# STM32WB09 register map
File version: 1.0
CPU: CM0+ r0p0, little endian, MPU, no FPU, 2 interrupt priority bits
Registers are 32-bit, read-write, reset 0x0 unless marked. A register's access mark holds for its fields unless they carry their own. Offsets are from the block's base; [hi:lo] are bit positions.

## IWDG
Base 0x40003000
0x00 KR 16-bit — IWDG_KR register
  [15:0] KEY wo — Key value. Software can only write these bits. Reading returns the reset value. These bits must be written by software at regular intervals with the key value 0xAAAA, otherwise the watchdog generates a reset when the counter reaches 0. Writing the key value 0x5555 to enables access to the IWDG_PR, IWDG_RLR and IWDG_WINR registers. Writing the key value CCCCh starts the watchdog
    0x5555=Unlock (Enable access to PR, RLR and WINR registers); 0xAAAA=Feed watchdog with RLR register value; 0xCCCC=Start the watchdog
0x04 PR 16-bit — IWDG_PR register
  [2:0] PR — Prescaler divider. Set and reset by software. These bits are write access protected. They are written by software to select the prescaler divider feeding the counter clock. PVU bit of IWDG_SR must be reset in order to be able to change the prescaler divider. 000: divider/4 001: divider/8 010: divider/16 011: divider/32 100: divider/64 101: divider/128 110: divider/256 111: divider/256
    0=DivideBy4 (Divider /4); 1=DivideBy8 (Divider /8); 2=DivideBy16 (Divider /16); 3=DivideBy32 (Divider /32); 4=DivideBy64 (Divider /64); 5=DivideBy128 (Divider /128); other=DivideBy256 (Divider /256)
0x08 RLR 16-bit reset 0xFFF — IWDG_RLR register
  [11:0] RL — Watchdog counter reload value. Set and reset by software. These bits are write access protected. They are written by software to define the value to be loaded in the watchdog counter each time the value 0xAAAA is written in the IWDG_KR register. The watchdog counter counts down from this value. The timeout period is a function of this value and the clock prescaler. The RVU bit in the IWDG_SR register must be reset in order to be able to change the reload value.
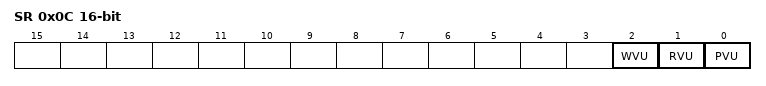
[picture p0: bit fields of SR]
0x0C SR 16-bit ro — IWDG_SR register
  [2] WVU — Watchdog counter window value update. Read only bit. This bit is set by hardware to indicate that an update of the window value is ongoing. It is reset by hardware when the reload value update operation is completed in the VDD voltage domain (takes up to 5 RC 40 kHz cycles). Window value can be updated only when WVU bit is reset. This bit is generated only if generic 'window' = 1
  [1] RVU — Watchdog counter reload value update. Read only bit. This bit is set by hardware to indicate that an update of the reload value is ongoing. It is reset by hardware when the reload value update operation is completed in the VDD voltage domain (takes up to 5 RC 40 kHz cycles). Reload value can be updated only when RVU bit is reset
  [0] PVU — Watchdog prescaler value update. Read only bit. This bit is set by hardware to indicate that an update of the prescaler value is ongoing. It is reset by hardware when the prescaler update operation is completed in the VDD voltage domain (takes up to 5 RC 40 kHz cycles). Prescaler value can be updated only when PVU bit is reset
0x10 WINR 16-bit reset 0xFFF — IWDG_WINR register
  [11:0] WIN — Watchdog counter window value. Set and reset by software. These bits are write access protected. These bits contain the high limit of the window value to be compared to the downcounter. To prevent a reset, the downcounter must be reloaded when its value is lower than the window register value and greater than 0x0 The WVU bit in the IWDG_SR register must be reset in order to be able to change the reload value.

## PKA
Base 0x48300000
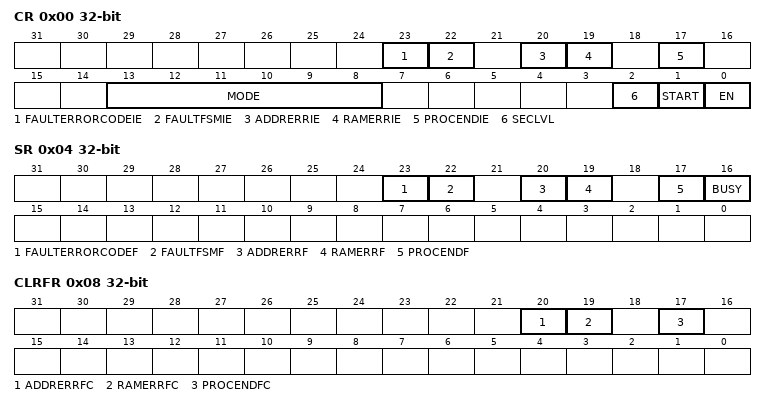
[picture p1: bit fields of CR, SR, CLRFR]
0x00 CR — PKA_CR register
  [23] FAULTERRORCODEIE — Fault error code interrupt enable 0: Interrupt is disabled. 1: An interrupt is generated when FAULTERRORCODEF (PKA_SR[23]) is set.
  [22] FAULTFSMIE — Fault FSM interrupt enable 0: Interrupt is disabled. 1: An interrupt is generated when FAULTFSMF (PKA_SR[22]) is set.
  [20] ADDRERRIE — Address error interrupt enable 0: Interrupt is disabled. 1: An interrupt is generated when ADDRERRF (PKA_SR[20]) is set.
  [19] RAMERRIE — RAM error interrupt enable 0: Interrupt is disabled. 1: An interrupt is generated when RAMERRF (PKA_SR[19]) is set.
  [17] PROCENDIE — End of operation interrupt enable 0: Interrupt is disabled. 1: An interrupt is generated when PROCENDF (PKA_SR[17]) is set.
  [13:8] MODE — PKA operation code 000000 : Compute Montgomery parameter and modular exponentiation 000001 : Compute Montgomery parameter 000010 : Compute modular exponentiation only (Montgomery parameter should be loaded) 100000 : Compute Montgomery parameter and compute ECC kP operation 100010 : Compute the ECC kP primitive only (Montgomery parameter should be loaded) 100100 : ECDSA sign 100110 : ECDSA Verification 101000 : Point Check 000111 : RSA CRT exponentiation 001000 : Modular inversion 001001 : Arithmetic addition 001010 : Arithmetic Subtraction 001011 : Arithmetic multiplication 001100 : Comparison 001101 : Modular Reduction 001110 : Modular Addition 001111 : Modular Subtraction 010000 : Montgomery Multiplication
  [2] SECLVL — Security enable. 0: No side channel countermeasure 1: Square and Multiply always / Double and Add always
  [1] START — Start the operation 0: No operation 1: Writing '1' to this bit starts the operation which is selected by MODE[5:0], using the operands and data already written to the PKA RAM. This bit is always read as '0'. Nota: START is ignored if PKA is busy.
  [0] EN — Peripheral enable. 0 : Disable PKA. 1 : Enable PKA.
0x04 SR ro — PKA_SR register
  [23] FAULTERRORCODEF — Fault error code error flag 0: No fault has been detected 1: A fault has altered the execution of the operation and the internal fault check has been skipped
  [22] FAULTFSMF — Fault fsm error flag 0: No fault has been detected 1: A fault on fsm has been detected
  [20] ADDRERRF — Address error flag 0: No Address error 1: Address access is out of range (unmapped address)
  [19] RAMERRF — PKA RAM error flag 0: No PKA RAM access error 1: An AHB access to the PKA RAM occured while the PKA core was computing and using its internal RAM (AHB PKA_RAM access are not allowed while PKA operation is in progress).
  [17] PROCENDF — PKA End of Operation flag 0: Operation in progress 1: PKA operation is completed. This flag is set when the BUSY bit is de-asserted.
  [16] BUSY — PKA operation is in progress This bit is set to '1' whenever START bit in the PKA_CR is set. It is automatically cleared when the computation is complete, meaning that PKA RAM can be safely accessed and a new operation can be started. 0: No operation is in progress (default) 1: An operation is in progress Nota: if PKA is started with a wrong opcode the IP will be busy for a couple of cycles then it will abort automatically the operation and go back to ready (BUSY bit is set to '0').
0x08 CLRFR — PKA_CLRFR register
  [20] ADDRERRFC — Clear Address error flag 0: No action 1: Clear the ADDRERRF flag
  [19] RAMERRFC — Clear PKA RAM error flag 0: No action 1: Clear the RAMERRF flag Bits 18 Reserved, must be kept at zero
  [17] PROCENDFC — Clear PKA End of Operation flag 0: No action 1: Clear the PROCENDF flag
